# MCAN0_ECC_MCAN0_ECC register map
Vendor: Texas Instruments
Peripheral module from a debugger description file (folder AM263).
Registers are 32-bit, read-write, reset 0x0 unless marked. A register's access mark holds for its fields unless they carry their own. Offsets are as the file gives them; lines under a group give offsets from that group; [hi:lo] are bit positions; {n}, {i} and the like mark numbered series; 'fields as' and 'values as' point back to an identical list; <NAME> marks a mode.

## MCAN0_ECC_MCAN0_ECC
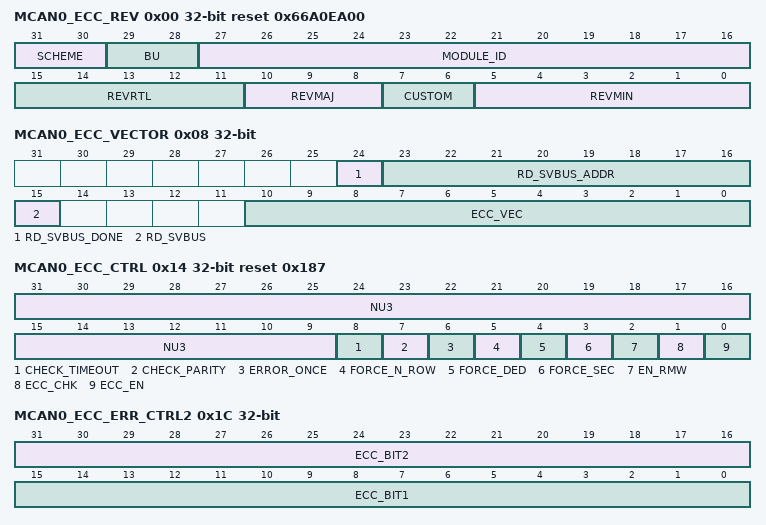
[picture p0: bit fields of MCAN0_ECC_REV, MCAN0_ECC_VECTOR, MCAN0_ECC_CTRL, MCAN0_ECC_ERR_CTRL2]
0x00 MCAN0_ECC_REV ro reset 0x66A0EA00
  [31:30] SCHEME
  [29:28] BU
  [27:16] MODULE_ID
  [15:11] REVRTL — RTL version
  [10:8] REVMAJ — Major version
  [7:6] CUSTOM — Custom version
  [5:0] REVMIN — Minor version
0x08 MCAN0_ECC_VECTOR
  [24] RD_SVBUS_DONE — Status to indicate if read on serial VBUS is complete, write of any value will clear this bit. Writing 1 to any bit will clear the corresponding bits. Reads do not alter the value of the field.
  [23:16] RD_SVBUS_ADDR — Read address
  [15] RD_SVBUS — Write 1 to trigger a read on the serial VBUS. Writing 1 to any bit will set the corresponding bit. Reads do not alter the value of the field.
  [10:0] ECC_VEC — Value written to select the corresponding ECC RAM for control or status
0x0C MCAN0_ECC_STAT ro reset 0x2
  [10:0] NUM_RAMS — Indicates the number of RAMS serviced by the ECC aggregator
0x14 MCAN0_ECC_CTRL access per field reset 0x187
  [31:9] NU3 ro — TI Internal : Reserved
  [8] CHECK_TIMEOUT wo — TI Internal : Check timeout
  [7] CHECK_PARITY wo — TI Internal : Check Parity
  [6] ERROR_ONCE wo — TI Internal : Force Error only once
  [5] FORCE_N_ROW wo — TI Internal : Force Error on any RAM read
  [4] FORCE_DED wo — TI Internal : Force Double Bit Error
  [3] FORCE_SEC wo — TI Internal : Force Single Bit Error
  [2] EN_RMW wo — TI Internal : Enable rmw
  [1] ECC_CHK wo — TI Internal : Enable ECC check
  [0] ECC_EN wo — TI Internal : Enable ECC
0x18 MCAN0_ECC_ERR_CTRL1
  [31:0] ECC_ROW — TI Internal : Row address where single or double-bit error needs to be applied. This is ignored if force_n_row is set
0x1C MCAN0_ECC_ERR_CTRL2
  [31:16] ECC_BIT2 — TI Internal : Data bit that needs to be flipped if double bit error needs to be forced
  [15:0] ECC_BIT1 — TI Internal : Data bit that needs to be flipped when force_sec is set
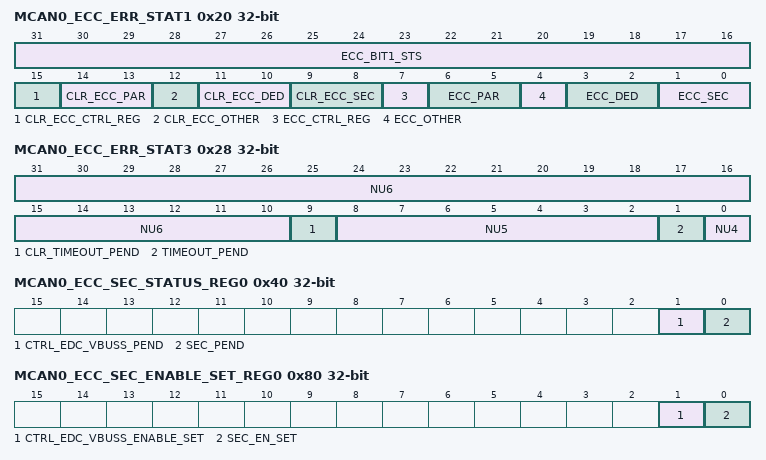
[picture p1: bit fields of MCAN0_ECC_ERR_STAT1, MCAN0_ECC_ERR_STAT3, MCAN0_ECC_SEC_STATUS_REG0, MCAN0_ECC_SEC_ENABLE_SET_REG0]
0x20 MCAN0_ECC_ERR_STAT1 access per field
  [31:16] ECC_BIT1_STS ro — TI Internal : Data bit that corresponds to the single-bit error
  [15] CLR_ECC_CTRL_REG wo — TI Internal : Clear Ctrl Reg Error Status. Write 1 to clear. This bit is self clearing.
  [14:13] CLR_ECC_PAR wo — TI Internal : Clear Parity Error Status. Write 1 to clear. This bit is self clearing.
  [12] CLR_ECC_OTHER wo — TI Internal : Clear Other Error Status. Write 1 to clear. This bit is self clearing.
  [11:10] CLR_ECC_DED wo — TI Internal : Clear Double Bit Error Status. Write 1 to clear. This bit is self clearing.
  [9:8] CLR_ECC_SEC wo — TI Internal : Clear Single Bit Error Status. Write 1 to clear. This bit is self clearing.
  [7] ECC_CTRL_REG wo — TI Internal : Force ctrl reg pending interrupt. Write 1 to set. This bit is self clearing.
  [6:5] ECC_PAR wo — TI Internal : Force ECC parity pending interrupt. Write 1 to set. This bit is self clearing.
  [4] ECC_OTHER wo — TI Internal : Force ECC other pending interrupt. Write 1 to set. This bit is self clearing.
  [3:2] ECC_DED wo — TI Internal : Force ECC DED pending interrupt. Write 1 to set. This bit is self clearing.
  [1:0] ECC_SEC wo — TI Internal : Force ECC SEC pending interrupt. Write 1 to set. This bit is self clearing.
0x24 MCAN0_ECC_ERR_STAT2 ro
  [31:0] ECC_ROW — TI Internal : Row address where the single or double-bit error has occurred
0x28 MCAN0_ECC_ERR_STAT3 access per field
  [31:10] NU6 ro — TI Internal : Reserved
  [9] CLR_TIMEOUT_PEND wo — TI Internal : Clear timeout pending
  [8:2] NU5 ro — TI Internal : Reserved
  [1] TIMEOUT_PEND wo — TI Internal : Timeout pending
  [0] NU4 ro — TI Internal : Reserved
0x3C MCAN0_ECC_SEC_EOI_REG
  [0] SEC_EOI_WR — EOI Register. Writing 1 to any bit will set the corresponding bit. Reads do not alter the value of the field. This bit is self clearing, reading this bit will return 0.
0x40 MCAN0_ECC_SEC_STATUS_REG0 ro
  [1] CTRL_EDC_VBUSS_PEND — Interrupt Pending Status for ctrl_edc_vbuss_pend.
  [0] SEC_PEND — Interrupt Pending Status for msgmem_pend.
0x80 MCAN0_ECC_SEC_ENABLE_SET_REG0
  [1] CTRL_EDC_VBUSS_ENABLE_SET — Interrupt Enable Set Register for ctrl_edc_vbuss_pend. Writing 1 to any bit will set the corresponding bit. Reads do not alter the value of the field.
  [0] SEC_EN_SET — Interrupt Enable Set Register for msgmem_pend. Writing 1 to any bit will set the corresponding bit. Reads do not alter the value of the field.
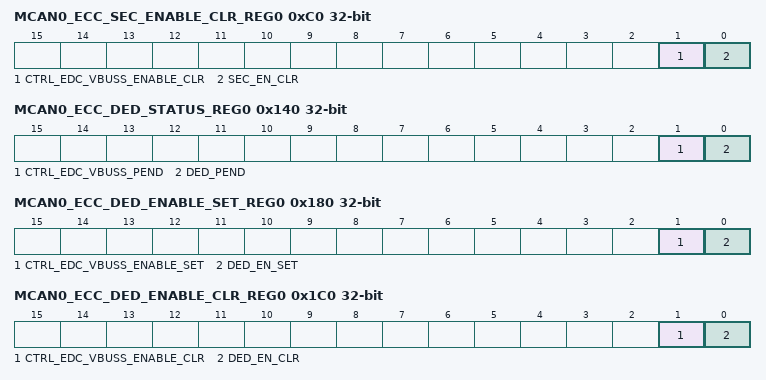
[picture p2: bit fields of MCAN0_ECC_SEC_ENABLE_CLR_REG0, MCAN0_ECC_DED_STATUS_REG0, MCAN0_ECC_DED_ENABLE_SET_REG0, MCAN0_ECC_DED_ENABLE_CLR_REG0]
0xC0 MCAN0_ECC_SEC_ENABLE_CLR_REG0
  [1] CTRL_EDC_VBUSS_ENABLE_CLR — Interrupt Enable Clear Register for ctrl_edc_vbuss_pend. Writing 1 to any bit will clear the corresponding bits. Reads do not alter the value of the field. Reading this bit will return 0.
  [0] SEC_EN_CLR — Interrupt Enable Clear Register for msgmem_pend. Writing 1 to any bit will clear the corresponding bits. Reads do not alter the value of the field. Reading this bit will return 0.
0x13C MCAN0_ECC_DED_EOI_REG
  [0] DED_EOI_WR — EOI Register. Writing 1 to any bit will set the corresponding bit. Reads do not alter the value of the field. This bit is self clearing, reading this bit will return 0.
0x140 MCAN0_ECC_DED_STATUS_REG0 ro
  [1] CTRL_EDC_VBUSS_PEND — Interrupt Pending Status for ctrl_edc_vbuss_pend.
  [0] DED_PEND — Interrupt Pending Status for msgmem_pend.
0x180 MCAN0_ECC_DED_ENABLE_SET_REG0
  [1] CTRL_EDC_VBUSS_ENABLE_SET — Interrupt Enable Set Register for ctrl_edc_vbuss_pend. Writing 1 to any bit will set the corresponding bit. Reads do not alter the value of the field.
  [0] DED_EN_SET — Interrupt Enable Set Register for msgmem_pend. Writing 1 to any bit will set the corresponding bit. Reads do not alter the value of the field.
0x1C0 MCAN0_ECC_DED_ENABLE_CLR_REG0
  [1] CTRL_EDC_VBUSS_ENABLE_CLR — Interrupt Enable Clear Register for ctrl_edc_vbuss_pend. Writing 1 to any bit will clear the corresponding bits. Reads do not alter the value of the field. Reading this bit will return 0.
  [0] DED_EN_CLR — Interrupt Enable Clear Register for msgmem_pend. Writing 1 to any bit will clear the corresponding bits. Reads do not alter the value of the field. Reading this bit will return 0.
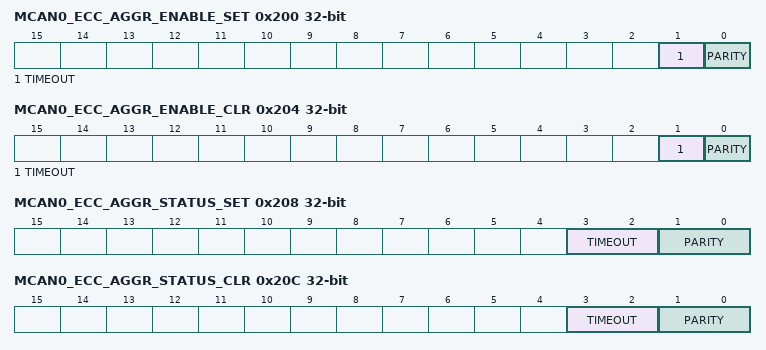
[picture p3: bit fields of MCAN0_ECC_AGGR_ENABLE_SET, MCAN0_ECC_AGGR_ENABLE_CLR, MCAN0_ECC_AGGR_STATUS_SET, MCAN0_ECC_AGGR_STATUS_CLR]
0x200 MCAN0_ECC_AGGR_ENABLE_SET
  [1] TIMEOUT — Interrupt Enable Set Register for svbus timeout errors. Writing 1 to any bit will set the corresponding bit. Reads do not alter the value of the field.
  [0] PARITY — Interrupt Enable Set Register for parity errors. Writing 1 to any bit will set the corresponding bit. Reads do not alter the value of the field.
0x204 MCAN0_ECC_AGGR_ENABLE_CLR
  [1] TIMEOUT — Interrupt Enable Clear for svbus timeout errors. Writing 1 to any bit will clear the corresponding bits. Reads do not alter the value of the field. Reading this bit will return 0.
  [0] PARITY — Interrupt Enable Clear for parity errors. Writing 1 to any bit will clear the corresponding bits. Reads do not alter the value of the field. Reading this bit will return 0.
0x208 MCAN0_ECC_AGGR_STATUS_SET
  [3:2] TIMEOUT — Interrupt status set for svbus timeout errors. A write to increment field. Writing a value to this field increment the field value by the value written. Reads do not alter the value of the field.
  [1:0] PARITY — Interrupt status set for parity errors. A write to increment field. Writing a value to this field increment the field value by the value written. Reads do not alter the value of the field.
0x20C MCAN0_ECC_AGGR_STATUS_CLR
  [3:2] TIMEOUT — Interrupt status clear for svbus timeout errors. A write to decrement field. Writing a value to this field decrements the field value by the value written. Reads do not alter the value of the field.
  [1:0] PARITY — Interrupt status clear for parity errors. A write to decrement field. Writing a value to this field decrements the field value by the value written. Reads do not alter the value of the field.
